AUTOSAR XML (schema 4-3-0)
standard types defined: Boolean, UInt8, SInt8, UInt16, SInt16, UInt32, SInt32, boolean, uint8, sint8, uint16, sint16, uint32, sint32
package /Components
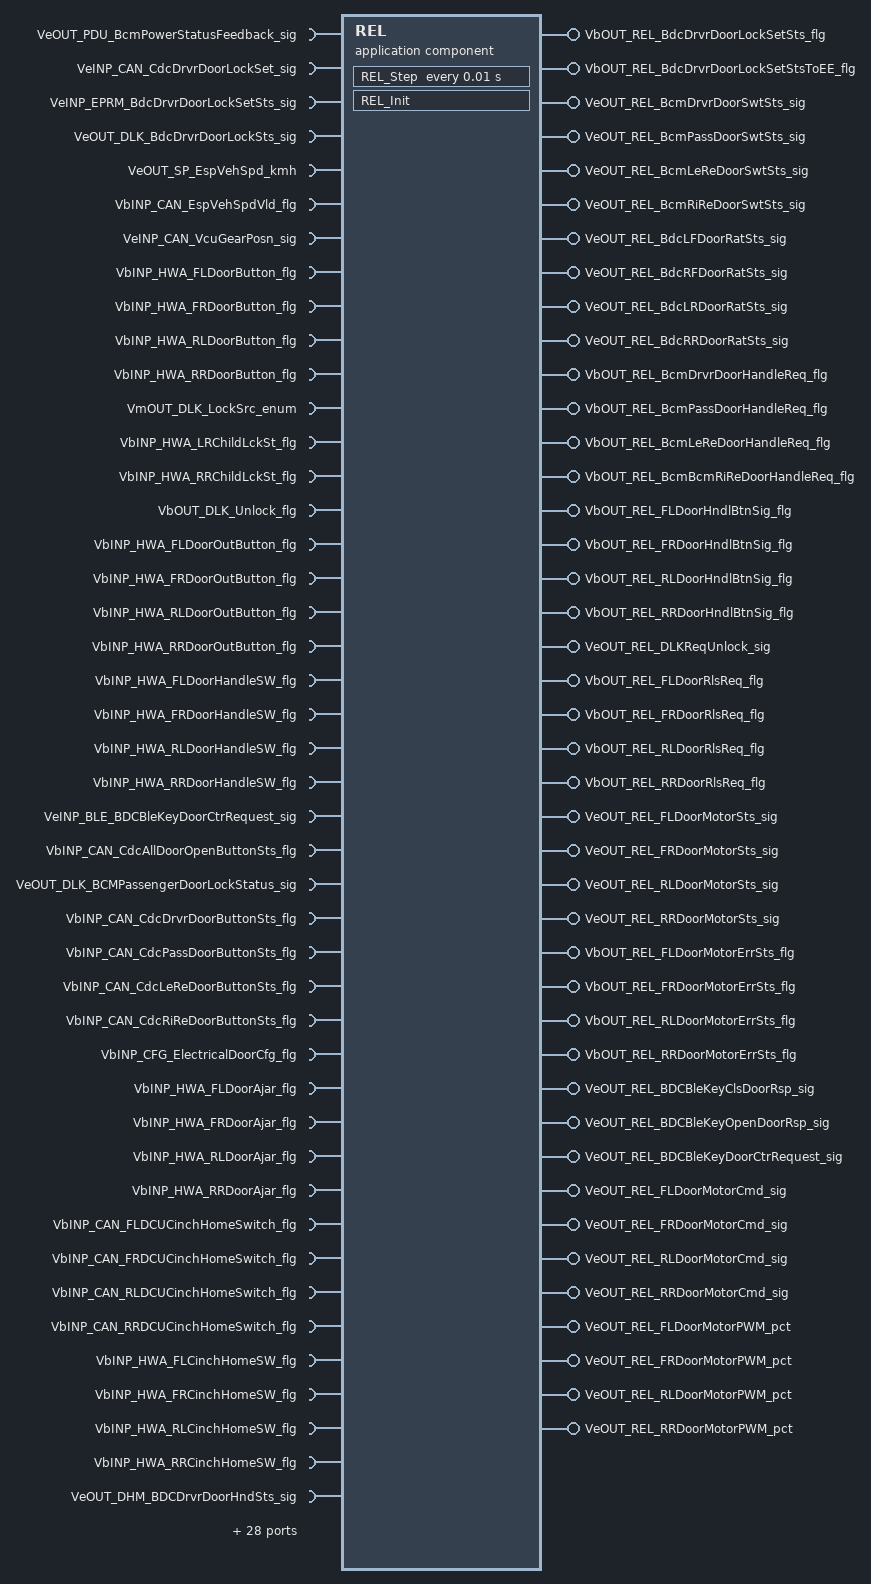
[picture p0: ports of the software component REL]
  application sw component type REL
    74 x require port:
      VeOUT_PDU_BcmPowerStatusFeedback_sig: nonqueued-receiver-com-spec{data-element=VeOUT_PDU_BcmPowerStatusFeedback_sig, init-value=0}, required-interface=VeOUT_PDU_BcmPowerStatusFeedback_sig
      VeINP_CAN_CdcDrvrDoorLockSet_sig: nonqueued-receiver-com-spec{data-element=VeINP_CAN_CdcDrvrDoorLockSet_sig, init-value=0}, required-interface=VeINP_CAN_CdcDrvrDoorLockSet_sig
      VeINP_EPRM_BdcDrvrDoorLockSetSts_sig: nonqueued-receiver-com-spec{data-element=VeINP_EPRM_BdcDrvrDoorLockSetSts_sig, init-value=0}, required-interface=VeINP_EPRM_BdcDrvrDoorLockSetSts_sig
      VeOUT_DLK_BdcDrvrDoorLockSts_sig: nonqueued-receiver-com-spec{data-element=VeOUT_DLK_BdcDrvrDoorLockSts_sig, init-value=0}, required-interface=VeOUT_DLK_BdcDrvrDoorLockSts_sig
      VeOUT_SP_EspVehSpd_kmh: nonqueued-receiver-com-spec{data-element=VeOUT_SP_EspVehSpd_kmh, init-value=0}, required-interface=VeOUT_SP_EspVehSpd_kmh
      VbINP_CAN_EspVehSpdVld_flg: nonqueued-receiver-com-spec{data-element=VbINP_CAN_EspVehSpdVld_flg, init-value=0}, required-interface=VbINP_CAN_EspVehSpdVld_flg
      VeINP_CAN_VcuGearPosn_sig: nonqueued-receiver-com-spec{data-element=VeINP_CAN_VcuGearPosn_sig, init-value=0}, required-interface=VeINP_CAN_VcuGearPosn_sig
      VbINP_HWA_FLDoorButton_flg: nonqueued-receiver-com-spec{data-element=VbINP_HWA_FLDoorButton_flg, init-value=0}, required-interface=VbINP_HWA_FLDoorButton_flg
      VbINP_HWA_FRDoorButton_flg: nonqueued-receiver-com-spec{data-element=VbINP_HWA_FRDoorButton_flg, init-value=0}, required-interface=VbINP_HWA_FRDoorButton_flg
      VbINP_HWA_RLDoorButton_flg: nonqueued-receiver-com-spec{data-element=VbINP_HWA_RLDoorButton_flg, init-value=0}, required-interface=VbINP_HWA_RLDoorButton_flg
      VbINP_HWA_RRDoorButton_flg: nonqueued-receiver-com-spec{data-element=VbINP_HWA_RRDoorButton_flg, init-value=0}, required-interface=VbINP_HWA_RRDoorButton_flg
      VmOUT_DLK_LockSrc_enum: nonqueued-receiver-com-spec{data-element=VmOUT_DLK_LockSrc_enum, init-value=0}, required-interface=VmOUT_DLK_LockSrc_enum
      VbINP_HWA_LRChildLckSt_flg: nonqueued-receiver-com-spec{data-element=VbINP_HWA_LRChildLckSt_flg, init-value=0}, required-interface=VbINP_HWA_LRChildLckSt_flg
      VbINP_HWA_RRChildLckSt_flg: nonqueued-receiver-com-spec{data-element=VbINP_HWA_RRChildLckSt_flg, init-value=0}, required-interface=VbINP_HWA_RRChildLckSt_flg
      VbOUT_DLK_Unlock_flg: nonqueued-receiver-com-spec{data-element=VbOUT_DLK_Unlock_flg, init-value=0}, required-interface=VbOUT_DLK_Unlock_flg
      VbINP_HWA_FLDoorOutButton_flg: nonqueued-receiver-com-spec{data-element=VbINP_HWA_FLDoorOutButton_flg, init-value=0}, required-interface=VbINP_HWA_FLDoorOutButton_flg
      VbINP_HWA_FRDoorOutButton_flg: nonqueued-receiver-com-spec{data-element=VbINP_HWA_FRDoorOutButton_flg, init-value=0}, required-interface=VbINP_HWA_FRDoorOutButton_flg
      VbINP_HWA_RLDoorOutButton_flg: nonqueued-receiver-com-spec{data-element=VbINP_HWA_RLDoorOutButton_flg, init-value=0}, required-interface=VbINP_HWA_RLDoorOutButton_flg
      VbINP_HWA_RRDoorOutButton_flg: nonqueued-receiver-com-spec{data-element=VbINP_HWA_RRDoorOutButton_flg, init-value=0}, required-interface=VbINP_HWA_RRDoorOutButton_flg
      VbINP_HWA_FLDoorHandleSW_flg: nonqueued-receiver-com-spec{data-element=VbINP_HWA_FLDoorHandleSW_flg, init-value=0}, required-interface=VbINP_HWA_FLDoorHandleSW_flg
      VbINP_HWA_FRDoorHandleSW_flg: nonqueued-receiver-com-spec{data-element=VbINP_HWA_FRDoorHandleSW_flg, init-value=0}, required-interface=VbINP_HWA_FRDoorHandleSW_flg
      VbINP_HWA_RLDoorHandleSW_flg: nonqueued-receiver-com-spec{data-element=VbINP_HWA_RLDoorHandleSW_flg, init-value=0}, required-interface=VbINP_HWA_RLDoorHandleSW_flg
      VbINP_HWA_RRDoorHandleSW_flg: nonqueued-receiver-com-spec{data-element=VbINP_HWA_RRDoorHandleSW_flg, init-value=0}, required-interface=VbINP_HWA_RRDoorHandleSW_flg
      VeINP_BLE_BDCBleKeyDoorCtrRequest_sig: nonqueued-receiver-com-spec{data-element=VeINP_BLE_BDCBleKeyDoorCtrRequest_sig, init-value=0}, required-interface=VeINP_BLE_BDCBleKeyDoorCtrRequest_sig
      VbINP_CAN_CdcAllDoorOpenButtonSts_flg: nonqueued-receiver-com-spec{data-element=VbINP_CAN_CdcAllDoorOpenButtonSts_flg, init-value=0}, required-interface=VbINP_CAN_CdcAllDoorOpenButtonSts_flg
      VeOUT_DLK_BCMPassengerDoorLockStatus_sig: nonqueued-receiver-com-spec{data-element=VeOUT_DLK_BCMPassengerDoorLockStatus_sig, init-value=0}, required-interface=VeOUT_DLK_BCMPassengerDoorLockStatus_sig
      VbINP_CAN_CdcDrvrDoorButtonSts_flg: nonqueued-receiver-com-spec{data-element=VbINP_CAN_CdcDrvrDoorButtonSts_flg, init-value=0}, required-interface=VbINP_CAN_CdcDrvrDoorButtonSts_flg
      VbINP_CAN_CdcPassDoorButtonSts_flg: nonqueued-receiver-com-spec{data-element=VbINP_CAN_CdcPassDoorButtonSts_flg, init-value=0}, required-interface=VbINP_CAN_CdcPassDoorButtonSts_flg
      VbINP_CAN_CdcLeReDoorButtonSts_flg: nonqueued-receiver-com-spec{data-element=VbINP_CAN_CdcLeReDoorButtonSts_flg, init-value=0}, required-interface=VbINP_CAN_CdcLeReDoorButtonSts_flg
      VbINP_CAN_CdcRiReDoorButtonSts_flg: nonqueued-receiver-com-spec{data-element=VbINP_CAN_CdcRiReDoorButtonSts_flg, init-value=0}, required-interface=VbINP_CAN_CdcRiReDoorButtonSts_flg
      VbINP_CFG_ElectricalDoorCfg_flg: nonqueued-receiver-com-spec{data-element=VbINP_CFG_ElectricalDoorCfg_flg, init-value=0}, required-interface=VbINP_CFG_ElectricalDoorCfg_flg
      VbINP_HWA_FLDoorAjar_flg: nonqueued-receiver-com-spec{data-element=VbINP_HWA_FLDoorAjar_flg, init-value=0}, required-interface=VbINP_HWA_FLDoorAjar_flg
      VbINP_HWA_FRDoorAjar_flg: nonqueued-receiver-com-spec{data-element=VbINP_HWA_FRDoorAjar_flg, init-value=0}, required-interface=VbINP_HWA_FRDoorAjar_flg
      VbINP_HWA_RLDoorAjar_flg: nonqueued-receiver-com-spec{data-element=VbINP_HWA_RLDoorAjar_flg, init-value=0}, required-interface=VbINP_HWA_RLDoorAjar_flg
      VbINP_HWA_RRDoorAjar_flg: nonqueued-receiver-com-spec{data-element=VbINP_HWA_RRDoorAjar_flg, init-value=0}, required-interface=VbINP_HWA_RRDoorAjar_flg
      VbINP_CAN_FLDCUCinchHomeSwitch_flg: nonqueued-receiver-com-spec{data-element=VbINP_CAN_FLDCUCinchHomeSwitch_flg, init-value=0}, required-interface=VbINP_CAN_FLDCUCinchHomeSwitch_flg
      VbINP_CAN_FRDCUCinchHomeSwitch_flg: nonqueued-receiver-com-spec{data-element=VbINP_CAN_FRDCUCinchHomeSwitch_flg, init-value=0}, required-interface=VbINP_CAN_FRDCUCinchHomeSwitch_flg
      VbINP_CAN_RLDCUCinchHomeSwitch_flg: nonqueued-receiver-com-spec{data-element=VbINP_CAN_RLDCUCinchHomeSwitch_flg, init-value=0}, required-interface=VbINP_CAN_RLDCUCinchHomeSwitch_flg
      VbINP_CAN_RRDCUCinchHomeSwitch_flg: nonqueued-receiver-com-spec{data-element=VbINP_CAN_RRDCUCinchHomeSwitch_flg, init-value=0}, required-interface=VbINP_CAN_RRDCUCinchHomeSwitch_flg
      VbINP_HWA_FLCinchHomeSW_flg: nonqueued-receiver-com-spec{data-element=VbINP_HWA_FLCinchHomeSW_flg, init-value=0}, required-interface=VbINP_HWA_FLCinchHomeSW_flg
      VbINP_HWA_FRCinchHomeSW_flg: nonqueued-receiver-com-spec{data-element=VbINP_HWA_FRCinchHomeSW_flg, init-value=0}, required-interface=VbINP_HWA_FRCinchHomeSW_flg
      VbINP_HWA_RLCinchHomeSW_flg: nonqueued-receiver-com-spec{data-element=VbINP_HWA_RLCinchHomeSW_flg, init-value=0}, required-interface=VbINP_HWA_RLCinchHomeSW_flg
      VbINP_HWA_RRCinchHomeSW_flg: nonqueued-receiver-com-spec{data-element=VbINP_HWA_RRCinchHomeSW_flg, init-value=0}, required-interface=VbINP_HWA_RRCinchHomeSW_flg
      VeOUT_DHM_BDCDrvrDoorHndSts_sig: nonqueued-receiver-com-spec{data-element=VeOUT_DHM_BDCDrvrDoorHndSts_sig, init-value=0}, required-interface=VeOUT_DHM_BDCDrvrDoorHndSts_sig
      VeOUT_DHM_BDCPassDoorHndSts_sig: nonqueued-receiver-com-spec{data-element=VeOUT_DHM_BDCPassDoorHndSts_sig, init-value=0}, required-interface=VeOUT_DHM_BDCPassDoorHndSts_sig
      VeOUT_DHM_BDCLeReDoorHndSts_sig: nonqueued-receiver-com-spec{data-element=VeOUT_DHM_BDCLeReDoorHndSts_sig, init-value=0}, required-interface=VeOUT_DHM_BDCLeReDoorHndSts_sig
      VeOUT_DHM_BDCRiReDoorHndSts_sig: nonqueued-receiver-com-spec{data-element=VeOUT_DHM_BDCRiReDoorHndSts_sig, init-value=0}, required-interface=VeOUT_DHM_BDCRiReDoorHndSts_sig
      VbOUT_SP_CrashOutpSts_flg: nonqueued-receiver-com-spec{data-element=VbOUT_SP_CrashOutpSts_flg, init-value=0}, required-interface=VbOUT_SP_CrashOutpSts_flg
      VbOUT_DLK_BdcDrvrDoorLockOpenReq_flg: nonqueued-receiver-com-spec{data-element=VbOUT_DLK_BdcDrvrDoorLockOpenReq_flg, init-value=0}, required-interface=VbOUT_DLK_BdcDrvrDoorLockOpenReq_flg
      VbOUT_DHM_BdcDrivDoorHandButtonSts_flg: nonqueued-receiver-com-spec{data-element=VbOUT_DHM_BdcDrivDoorHandButtonSts_flg, init-value=0}, required-interface=VbOUT_DHM_BdcDrivDoorHandButtonSts_flg
      VbOUT_DHM_BdcPassDoorHandButtonSts_flg: nonqueued-receiver-com-spec{data-element=VbOUT_DHM_BdcPassDoorHandButtonSts_flg, init-value=0}, required-interface=VbOUT_DHM_BdcPassDoorHandButtonSts_flg
      VeINP_BLE_BleKey{1..3}Posn_sig: nonqueued-receiver-com-spec{data-element=VeINP_BLE_BleKey{1..3}Posn_sig, init-value=0}, required-interface=VeINP_BLE_BleKey{1..3}Posn_sig
      VuINP_CFG_TiLongPressHndlBtn_sig: nonqueued-receiver-com-spec{data-element=VuINP_CFG_TiLongPressHndlBtn_sig, init-value=0}, required-interface=VuINP_CFG_TiLongPressHndlBtn_sig
      VuINP_CFG_OutsideDoorOpenDelay_sig: nonqueued-receiver-com-spec{data-element=VuINP_CFG_OutsideDoorOpenDelay_sig, init-value=0}, required-interface=VuINP_CFG_OutsideDoorOpenDelay_sig
      VuINP_CFG_InsideDoorOpenDelay_sig: nonqueued-receiver-com-spec{data-element=VuINP_CFG_InsideDoorOpenDelay_sig, init-value=0}, required-interface=VuINP_CFG_InsideDoorOpenDelay_sig
      VuINP_CFG_Ti2xPressDoorSw_sig: nonqueued-receiver-com-spec{data-element=VuINP_CFG_Ti2xPressDoorSw_sig, init-value=0}, required-interface=VuINP_CFG_Ti2xPressDoorSw_sig
      VuINP_CFG_TiRelsActv_sig: nonqueued-receiver-com-spec{data-element=VuINP_CFG_TiRelsActv_sig, init-value=0}, required-interface=VuINP_CFG_TiRelsActv_sig
      VeINP_CFG_TiRelsBrakeActv_sig: nonqueued-receiver-com-spec{data-element=VeINP_CFG_TiRelsBrakeActv_sig, init-value=0}, required-interface=VeINP_CFG_TiRelsBrakeActv_sig
      VuINP_CFG_TiRelsResetActv_sig: nonqueued-receiver-com-spec{data-element=VuINP_CFG_TiRelsResetActv_sig, init-value=0}, required-interface=VuINP_CFG_TiRelsResetActv_sig
      VuINP_CFG_TiRelsBrakehold_sig: nonqueued-receiver-com-spec{data-element=VuINP_CFG_TiRelsBrakehold_sig, init-value=0}, required-interface=VuINP_CFG_TiRelsBrakehold_sig
      VuINP_CFG_TiRelsBrakeholdDelay_sig: nonqueued-receiver-com-spec{data-element=VuINP_CFG_TiRelsBrakeholdDelay_sig, init-value=0}, required-interface=VuINP_CFG_TiRelsBrakeholdDelay_sig
      VuINP_CFG_TiIceBrakeActv_sig: nonqueued-receiver-com-spec{data-element=VuINP_CFG_TiIceBrakeActv_sig, init-value=0}, required-interface=VuINP_CFG_TiIceBrakeActv_sig
      VeINP_CFG_VoltRelsActv_sig: nonqueued-receiver-com-spec{data-element=VeINP_CFG_VoltRelsActv_sig, init-value=0}, required-interface=VeINP_CFG_VoltRelsActv_sig
      VeINP_CFG_VoltRelsBrakeActv_sig: nonqueued-receiver-com-spec{data-element=VeINP_CFG_VoltRelsBrakeActv_sig, init-value=0}, required-interface=VeINP_CFG_VoltRelsBrakeActv_sig
      VeINP_CFG_TiCrashRelsDiable_sig: nonqueued-receiver-com-spec{data-element=VeINP_CFG_TiCrashRelsDiable_sig, init-value=0}, required-interface=VeINP_CFG_TiCrashRelsDiable_sig
      VeINP_CFG_TiBleOpenDoorFb_sig: nonqueued-receiver-com-spec{data-element=VeINP_CFG_TiBleOpenDoorFb_sig, init-value=0}, required-interface=VeINP_CFG_TiBleOpenDoorFb_sig
      VeINP_CFG_TiBleClsDoorFb_sig: nonqueued-receiver-com-spec{data-element=VeINP_CFG_TiBleClsDoorFb_sig, init-value=0}, required-interface=VeINP_CFG_TiBleClsDoorFb_sig
      VeINP_HWA_Voltage_100mV: nonqueued-receiver-com-spec{data-element=VeINP_HWA_Voltage_100mV, init-value=0}, required-interface=VeINP_HWA_Voltage_100mV
      VbINP_HWA_FLDoorOpenSW_flg: nonqueued-receiver-com-spec{data-element=VbINP_HWA_FLDoorOpenSW_flg, init-value=0}, required-interface=VbINP_HWA_FLDoorOpenSW_flg
      VbINP_HWA_FRDoorOpenSW_flg: nonqueued-receiver-com-spec{data-element=VbINP_HWA_FRDoorOpenSW_flg, init-value=0}, required-interface=VbINP_HWA_FRDoorOpenSW_flg
      VbINP_HWA_RLDoorOpenSW_flg: nonqueued-receiver-com-spec{data-element=VbINP_HWA_RLDoorOpenSW_flg, init-value=0}, required-interface=VbINP_HWA_RLDoorOpenSW_flg
      VbINP_HWA_RRDoorOpenSW_flg: nonqueued-receiver-com-spec{data-element=VbINP_HWA_RRDoorOpenSW_flg, init-value=0}, required-interface=VbINP_HWA_RRDoorOpenSW_flg
    42 x provide port:
      VbOUT_REL_BdcDrvrDoorLockSetSts_flg: nonqueued-sender-com-spec{data-element=VbOUT_REL_BdcDrvrDoorLockSetSts_flg, init-value=0}, provided-interface=VbOUT_REL_BdcDrvrDoorLockSetSts_flg
      VbOUT_REL_BdcDrvrDoorLockSetStsToEE_flg: nonqueued-sender-com-spec{data-element=VbOUT_REL_BdcDrvrDoorLockSetStsToEE_flg, init-value=0}, provided-interface=VbOUT_REL_BdcDrvrDoorLockSetStsToEE_flg
      VeOUT_REL_BcmDrvrDoorSwtSts_sig: nonqueued-sender-com-spec{data-element=VeOUT_REL_BcmDrvrDoorSwtSts_sig, init-value=0}, provided-interface=VeOUT_REL_BcmDrvrDoorSwtSts_sig
      VeOUT_REL_BcmPassDoorSwtSts_sig: nonqueued-sender-com-spec{data-element=VeOUT_REL_BcmPassDoorSwtSts_sig, init-value=0}, provided-interface=VeOUT_REL_BcmPassDoorSwtSts_sig
      VeOUT_REL_BcmLeReDoorSwtSts_sig: nonqueued-sender-com-spec{data-element=VeOUT_REL_BcmLeReDoorSwtSts_sig, init-value=0}, provided-interface=VeOUT_REL_BcmLeReDoorSwtSts_sig
      VeOUT_REL_BcmRiReDoorSwtSts_sig: nonqueued-sender-com-spec{data-element=VeOUT_REL_BcmRiReDoorSwtSts_sig, init-value=0}, provided-interface=VeOUT_REL_BcmRiReDoorSwtSts_sig
      VeOUT_REL_BdcLFDoorRatSts_sig: nonqueued-sender-com-spec{data-element=VeOUT_REL_BdcLFDoorRatSts_sig, init-value=0}, provided-interface=VeOUT_REL_BdcLFDoorRatSts_sig
      VeOUT_REL_BdcRFDoorRatSts_sig: nonqueued-sender-com-spec{data-element=VeOUT_REL_BdcRFDoorRatSts_sig, init-value=0}, provided-interface=VeOUT_REL_BdcRFDoorRatSts_sig
      VeOUT_REL_BdcLRDoorRatSts_sig: nonqueued-sender-com-spec{data-element=VeOUT_REL_BdcLRDoorRatSts_sig, init-value=0}, provided-interface=VeOUT_REL_BdcLRDoorRatSts_sig
      VeOUT_REL_BdcRRDoorRatSts_sig: nonqueued-sender-com-spec{data-element=VeOUT_REL_BdcRRDoorRatSts_sig, init-value=0}, provided-interface=VeOUT_REL_BdcRRDoorRatSts_sig
      VbOUT_REL_BcmDrvrDoorHandleReq_flg: nonqueued-sender-com-spec{data-element=VbOUT_REL_BcmDrvrDoorHandleReq_flg, init-value=0}, provided-interface=VbOUT_REL_BcmDrvrDoorHandleReq_flg
      VbOUT_REL_BcmPassDoorHandleReq_flg: nonqueued-sender-com-spec{data-element=VbOUT_REL_BcmPassDoorHandleReq_flg, init-value=0}, provided-interface=VbOUT_REL_BcmPassDoorHandleReq_flg
      VbOUT_REL_BcmLeReDoorHandleReq_flg: nonqueued-sender-com-spec{data-element=VbOUT_REL_BcmLeReDoorHandleReq_flg, init-value=0}, provided-interface=VbOUT_REL_BcmLeReDoorHandleReq_flg
      VbOUT_REL_BcmBcmRiReDoorHandleReq_flg: nonqueued-sender-com-spec{data-element=VbOUT_REL_BcmBcmRiReDoorHandleReq_flg, init-value=0}, provided-interface=VbOUT_REL_BcmBcmRiReDoorHandleReq_flg
      VbOUT_REL_FLDoorHndlBtnSig_flg: nonqueued-sender-com-spec{data-element=VbOUT_REL_FLDoorHndlBtnSig_flg, init-value=0}, provided-interface=VbOUT_REL_FLDoorHndlBtnSig_flg
      VbOUT_REL_FRDoorHndlBtnSig_flg: nonqueued-sender-com-spec{data-element=VbOUT_REL_FRDoorHndlBtnSig_flg, init-value=0}, provided-interface=VbOUT_REL_FRDoorHndlBtnSig_flg
      VbOUT_REL_RLDoorHndlBtnSig_flg: nonqueued-sender-com-spec{data-element=VbOUT_REL_RLDoorHndlBtnSig_flg, init-value=0}, provided-interface=VbOUT_REL_RLDoorHndlBtnSig_flg
      VbOUT_REL_RRDoorHndlBtnSig_flg: nonqueued-sender-com-spec{data-element=VbOUT_REL_RRDoorHndlBtnSig_flg, init-value=0}, provided-interface=VbOUT_REL_RRDoorHndlBtnSig_flg
      VeOUT_REL_DLKReqUnlock_sig: nonqueued-sender-com-spec{data-element=VeOUT_REL_DLKReqUnlock_sig, init-value=0}, provided-interface=VeOUT_REL_DLKReqUnlock_sig
      VbOUT_REL_FLDoorRlsReq_flg: nonqueued-sender-com-spec{data-element=VbOUT_REL_FLDoorRlsReq_flg, init-value=0}, provided-interface=VbOUT_REL_FLDoorRlsReq_flg
      VbOUT_REL_FRDoorRlsReq_flg: nonqueued-sender-com-spec{data-element=VbOUT_REL_FRDoorRlsReq_flg, init-value=0}, provided-interface=VbOUT_REL_FRDoorRlsReq_flg
      VbOUT_REL_RLDoorRlsReq_flg: nonqueued-sender-com-spec{data-element=VbOUT_REL_RLDoorRlsReq_flg, init-value=0}, provided-interface=VbOUT_REL_RLDoorRlsReq_flg
      VbOUT_REL_RRDoorRlsReq_flg: nonqueued-sender-com-spec{data-element=VbOUT_REL_RRDoorRlsReq_flg, init-value=0}, provided-interface=VbOUT_REL_RRDoorRlsReq_flg
      VeOUT_REL_FLDoorMotorSts_sig: nonqueued-sender-com-spec{data-element=VeOUT_REL_FLDoorMotorSts_sig, init-value=0}, provided-interface=VeOUT_REL_FLDoorMotorSts_sig
      VeOUT_REL_FRDoorMotorSts_sig: nonqueued-sender-com-spec{data-element=VeOUT_REL_FRDoorMotorSts_sig, init-value=0}, provided-interface=VeOUT_REL_FRDoorMotorSts_sig
      VeOUT_REL_RLDoorMotorSts_sig: nonqueued-sender-com-spec{data-element=VeOUT_REL_RLDoorMotorSts_sig, init-value=0}, provided-interface=VeOUT_REL_RLDoorMotorSts_sig
      VeOUT_REL_RRDoorMotorSts_sig: nonqueued-sender-com-spec{data-element=VeOUT_REL_RRDoorMotorSts_sig, init-value=0}, provided-interface=VeOUT_REL_RRDoorMotorSts_sig
      VbOUT_REL_FLDoorMotorErrSts_flg: nonqueued-sender-com-spec{data-element=VbOUT_REL_FLDoorMotorErrSts_flg, init-value=0}, provided-interface=VbOUT_REL_FLDoorMotorErrSts_flg
      VbOUT_REL_FRDoorMotorErrSts_flg: nonqueued-sender-com-spec{data-element=VbOUT_REL_FRDoorMotorErrSts_flg, init-value=0}, provided-interface=VbOUT_REL_FRDoorMotorErrSts_flg
      VbOUT_REL_RLDoorMotorErrSts_flg: nonqueued-sender-com-spec{data-element=VbOUT_REL_RLDoorMotorErrSts_flg, init-value=0}, provided-interface=VbOUT_REL_RLDoorMotorErrSts_flg
      VbOUT_REL_RRDoorMotorErrSts_flg: nonqueued-sender-com-spec{data-element=VbOUT_REL_RRDoorMotorErrSts_flg, init-value=0}, provided-interface=VbOUT_REL_RRDoorMotorErrSts_flg
      VeOUT_REL_BDCBleKeyClsDoorRsp_sig: nonqueued-sender-com-spec{data-element=VeOUT_REL_BDCBleKeyClsDoorRsp_sig, init-value=0}, provided-interface=VeOUT_REL_BDCBleKeyClsDoorRsp_sig
      VeOUT_REL_BDCBleKeyOpenDoorRsp_sig: nonqueued-sender-com-spec{data-element=VeOUT_REL_BDCBleKeyOpenDoorRsp_sig, init-value=0}, provided-interface=VeOUT_REL_BDCBleKeyOpenDoorRsp_sig
      VeOUT_REL_BDCBleKeyDoorCtrRequest_sig: nonqueued-sender-com-spec{data-element=VeOUT_REL_BDCBleKeyDoorCtrRequest_sig, init-value=0}, provided-interface=VeOUT_REL_BDCBleKeyDoorCtrRequest_sig
      VeOUT_REL_FLDoorMotorCmd_sig: nonqueued-sender-com-spec{data-element=VeOUT_REL_FLDoorMotorCmd_sig, init-value=0}, provided-interface=VeOUT_REL_FLDoorMotorCmd_sig
      VeOUT_REL_FRDoorMotorCmd_sig: nonqueued-sender-com-spec{data-element=VeOUT_REL_FRDoorMotorCmd_sig, init-value=0}, provided-interface=VeOUT_REL_FRDoorMotorCmd_sig
      VeOUT_REL_RLDoorMotorCmd_sig: nonqueued-sender-com-spec{data-element=VeOUT_REL_RLDoorMotorCmd_sig, init-value=0}, provided-interface=VeOUT_REL_RLDoorMotorCmd_sig
      VeOUT_REL_RRDoorMotorCmd_sig: nonqueued-sender-com-spec{data-element=VeOUT_REL_RRDoorMotorCmd_sig, init-value=0}, provided-interface=VeOUT_REL_RRDoorMotorCmd_sig
      VeOUT_REL_FLDoorMotorPWM_pct: nonqueued-sender-com-spec{data-element=VeOUT_REL_FLDoorMotorPWM_pct, init-value=0}, provided-interface=VeOUT_REL_FLDoorMotorPWM_pct
      VeOUT_REL_FRDoorMotorPWM_pct: nonqueued-sender-com-spec{data-element=VeOUT_REL_FRDoorMotorPWM_pct, init-value=0}, provided-interface=VeOUT_REL_FRDoorMotorPWM_pct
      VeOUT_REL_RLDoorMotorPWM_pct: nonqueued-sender-com-spec{data-element=VeOUT_REL_RLDoorMotorPWM_pct, init-value=0}, provided-interface=VeOUT_REL_RLDoorMotorPWM_pct
      VeOUT_REL_RRDoorMotorPWM_pct: nonqueued-sender-com-spec{data-element=VeOUT_REL_RRDoorMotorPWM_pct, init-value=0}, provided-interface=VeOUT_REL_RRDoorMotorPWM_pct
    behavior REL: data-type-mapping=DataTypeMappingsSet, handle-termination-and-restart=NO-SUPPORT
      init event REL_InitEvent: start-on-event=REL_Init
      timing event Event_Runnable_Step: start-on-event=REL_Step, period=0.01
      runnable REL_Init
      runnable REL_Step
        data-receive-point-by-arguments:
          74 x access:
            IN_VeOUT_PDU_BcmPowerStatusFeedback_sig_VeOUT_PDU_BcmPowerStatusFeedback_sig: accessed-variable=VeOUT_PDU_BcmPowerStatusFeedback_sig.VeOUT_PDU_BcmPowerStatusFeedback_sig
            IN_VeINP_CAN_CdcDrvrDoorLockSet_sig_VeINP_CAN_CdcDrvrDoorLockSet_sig: accessed-variable=VeINP_CAN_CdcDrvrDoorLockSet_sig.VeINP_CAN_CdcDrvrDoorLockSet_sig
            IN_VeINP_EPRM_BdcDrvrDoorLockSetSts_sig_VeINP_EPRM_BdcDrvrDoorLockSetSts_sig: accessed-variable=VeINP_EPRM_BdcDrvrDoorLockSetSts_sig.VeINP_EPRM_BdcDrvrDoorLockSetSts_sig
            IN_VeOUT_DLK_BdcDrvrDoorLockSts_sig_VeOUT_DLK_BdcDrvrDoorLockSts_sig: accessed-variable=VeOUT_DLK_BdcDrvrDoorLockSts_sig.VeOUT_DLK_BdcDrvrDoorLockSts_sig
            IN_VeOUT_SP_EspVehSpd_kmh_VeOUT_SP_EspVehSpd_kmh: accessed-variable=VeOUT_SP_EspVehSpd_kmh.VeOUT_SP_EspVehSpd_kmh
            IN_VbINP_CAN_EspVehSpdVld_flg_VbINP_CAN_EspVehSpdVld_flg: accessed-variable=VbINP_CAN_EspVehSpdVld_flg.VbINP_CAN_EspVehSpdVld_flg
            IN_VeINP_CAN_VcuGearPosn_sig_VeINP_CAN_VcuGearPosn_sig: accessed-variable=VeINP_CAN_VcuGearPosn_sig.VeINP_CAN_VcuGearPosn_sig
            IN_VbINP_HWA_FLDoorButton_flg_VbINP_HWA_FLDoorButton_flg: accessed-variable=VbINP_HWA_FLDoorButton_flg.VbINP_HWA_FLDoorButton_flg
            IN_VbINP_HWA_FRDoorButton_flg_VbINP_HWA_FRDoorButton_flg: accessed-variable=VbINP_HWA_FRDoorButton_flg.VbINP_HWA_FRDoorButton_flg
            IN_VbINP_HWA_RLDoorButton_flg_VbINP_HWA_RLDoorButton_flg: accessed-variable=VbINP_HWA_RLDoorButton_flg.VbINP_HWA_RLDoorButton_flg
            IN_VbINP_HWA_RRDoorButton_flg_VbINP_HWA_RRDoorButton_flg: accessed-variable=VbINP_HWA_RRDoorButton_flg.VbINP_HWA_RRDoorButton_flg
            IN_VmOUT_DLK_LockSrc_enum_VmOUT_DLK_LockSrc_enum: accessed-variable=VmOUT_DLK_LockSrc_enum.VmOUT_DLK_LockSrc_enum
            IN_VbINP_HWA_LRChildLckSt_flg_VbINP_HWA_LRChildLckSt_flg: accessed-variable=VbINP_HWA_LRChildLckSt_flg.VbINP_HWA_LRChildLckSt_flg
            IN_VbINP_HWA_RRChildLckSt_flg_VbINP_HWA_RRChildLckSt_flg: accessed-variable=VbINP_HWA_RRChildLckSt_flg.VbINP_HWA_RRChildLckSt_flg
            IN_VbOUT_DLK_Unlock_flg_VbOUT_DLK_Unlock_flg: accessed-variable=VbOUT_DLK_Unlock_flg.VbOUT_DLK_Unlock_flg
            IN_VbINP_HWA_FLDoorOutButton_flg_VbINP_HWA_FLDoorOutButton_flg: accessed-variable=VbINP_HWA_FLDoorOutButton_flg.VbINP_HWA_FLDoorOutButton_flg
            IN_VbINP_HWA_FRDoorOutButton_flg_VbINP_HWA_FRDoorOutButton_flg: accessed-variable=VbINP_HWA_FRDoorOutButton_flg.VbINP_HWA_FRDoorOutButton_flg
            IN_VbINP_HWA_RLDoorOutButton_flg_VbINP_HWA_RLDoorOutButton_flg: accessed-variable=VbINP_HWA_RLDoorOutButton_flg.VbINP_HWA_RLDoorOutButton_flg
            IN_VbINP_HWA_RRDoorOutButton_flg_VbINP_HWA_RRDoorOutButton_flg: accessed-variable=VbINP_HWA_RRDoorOutButton_flg.VbINP_HWA_RRDoorOutButton_flg
            IN_VbINP_HWA_FLDoorHandleSW_flg_VbINP_HWA_FLDoorHandleSW_flg: accessed-variable=VbINP_HWA_FLDoorHandleSW_flg.VbINP_HWA_FLDoorHandleSW_flg
            IN_VbINP_HWA_FRDoorHandleSW_flg_VbINP_HWA_FRDoorHandleSW_flg: accessed-variable=VbINP_HWA_FRDoorHandleSW_flg.VbINP_HWA_FRDoorHandleSW_flg
            IN_VbINP_HWA_RLDoorHandleSW_flg_VbINP_HWA_RLDoorHandleSW_flg: accessed-variable=VbINP_HWA_RLDoorHandleSW_flg.VbINP_HWA_RLDoorHandleSW_flg
            IN_VbINP_HWA_RRDoorHandleSW_flg_VbINP_HWA_RRDoorHandleSW_flg: accessed-variable=VbINP_HWA_RRDoorHandleSW_flg.VbINP_HWA_RRDoorHandleSW_flg
            IN_VeINP_BLE_BDCBleKeyDoorCtrRequest_sig_VeINP_BLE_BDCBleKeyDoorCtrRequest_sig: accessed-variable=VeINP_BLE_BDCBleKeyDoorCtrRequest_sig.VeINP_BLE_BDCBleKeyDoorCtrRequest_sig
            IN_VbINP_CAN_CdcAllDoorOpenButtonSts_flg_VbINP_CAN_CdcAllDoorOpenButtonSts_flg: accessed-variable=VbINP_CAN_CdcAllDoorOpenButtonSts_flg.VbINP_CAN_CdcAllDoorOpenButtonSts_flg
            IN_VeOUT_DLK_BCMPassengerDoorLockStatus_sig_VeOUT_DLK_BCMPassengerDoorLockStatus_sig: accessed-variable=VeOUT_DLK_BCMPassengerDoorLockStatus_sig.VeOUT_DLK_BCMPassengerDoorLockStatus_sig
            IN_VbINP_CAN_CdcDrvrDoorButtonSts_flg_VbINP_CAN_CdcDrvrDoorButtonSts_flg: accessed-variable=VbINP_CAN_CdcDrvrDoorButtonSts_flg.VbINP_CAN_CdcDrvrDoorButtonSts_flg
            IN_VbINP_CAN_CdcPassDoorButtonSts_flg_VbINP_CAN_CdcPassDoorButtonSts_flg: accessed-variable=VbINP_CAN_CdcPassDoorButtonSts_flg.VbINP_CAN_CdcPassDoorButtonSts_flg
            IN_VbINP_CAN_CdcLeReDoorButtonSts_flg_VbINP_CAN_CdcLeReDoorButtonSts_flg: accessed-variable=VbINP_CAN_CdcLeReDoorButtonSts_flg.VbINP_CAN_CdcLeReDoorButtonSts_flg
            IN_VbINP_CAN_CdcRiReDoorButtonSts_flg_VbINP_CAN_CdcRiReDoorButtonSts_flg: accessed-variable=VbINP_CAN_CdcRiReDoorButtonSts_flg.VbINP_CAN_CdcRiReDoorButtonSts_flg
            IN_VbINP_CFG_ElectricalDoorCfg_flg_VbINP_CFG_ElectricalDoorCfg_flg: accessed-variable=VbINP_CFG_ElectricalDoorCfg_flg.VbINP_CFG_ElectricalDoorCfg_flg
            IN_VbINP_HWA_FLDoorAjar_flg_VbINP_HWA_FLDoorAjar_flg: accessed-variable=VbINP_HWA_FLDoorAjar_flg.VbINP_HWA_FLDoorAjar_flg
            IN_VbINP_HWA_FRDoorAjar_flg_VbINP_HWA_FRDoorAjar_flg: accessed-variable=VbINP_HWA_FRDoorAjar_flg.VbINP_HWA_FRDoorAjar_flg
            IN_VbINP_HWA_RLDoorAjar_flg_VbINP_HWA_RLDoorAjar_flg: accessed-variable=VbINP_HWA_RLDoorAjar_flg.VbINP_HWA_RLDoorAjar_flg
            IN_VbINP_HWA_RRDoorAjar_flg_VbINP_HWA_RRDoorAjar_flg: accessed-variable=VbINP_HWA_RRDoorAjar_flg.VbINP_HWA_RRDoorAjar_flg
            IN_VbINP_CAN_FLDCUCinchHomeSwitch_flg_VbINP_CAN_FLDCUCinchHomeSwitch_flg: accessed-variable=VbINP_CAN_FLDCUCinchHomeSwitch_flg.VbINP_CAN_FLDCUCinchHomeSwitch_flg
            IN_VbINP_CAN_FRDCUCinchHomeSwitch_flg_VbINP_CAN_FRDCUCinchHomeSwitch_flg: accessed-variable=VbINP_CAN_FRDCUCinchHomeSwitch_flg.VbINP_CAN_FRDCUCinchHomeSwitch_flg
            IN_VbINP_CAN_RLDCUCinchHomeSwitch_flg_VbINP_CAN_RLDCUCinchHomeSwitch_flg: accessed-variable=VbINP_CAN_RLDCUCinchHomeSwitch_flg.VbINP_CAN_RLDCUCinchHomeSwitch_flg
            IN_VbINP_CAN_RRDCUCinchHomeSwitch_flg_VbINP_CAN_RRDCUCinchHomeSwitch_flg: accessed-variable=VbINP_CAN_RRDCUCinchHomeSwitch_flg.VbINP_CAN_RRDCUCinchHomeSwitch_flg
            IN_VbINP_HWA_FLCinchHomeSW_flg_VbINP_HWA_FLCinchHomeSW_flg: accessed-variable=VbINP_HWA_FLCinchHomeSW_flg.VbINP_HWA_FLCinchHomeSW_flg
            IN_VbINP_HWA_FRCinchHomeSW_flg_VbINP_HWA_FRCinchHomeSW_flg: accessed-variable=VbINP_HWA_FRCinchHomeSW_flg.VbINP_HWA_FRCinchHomeSW_flg
            IN_VbINP_HWA_RLCinchHomeSW_flg_VbINP_HWA_RLCinchHomeSW_flg: accessed-variable=VbINP_HWA_RLCinchHomeSW_flg.VbINP_HWA_RLCinchHomeSW_flg
            IN_VbINP_HWA_RRCinchHomeSW_flg_VbINP_HWA_RRCinchHomeSW_flg: accessed-variable=VbINP_HWA_RRCinchHomeSW_flg.VbINP_HWA_RRCinchHomeSW_flg
            IN_VeOUT_DHM_BDCDrvrDoorHndSts_sig_VeOUT_DHM_BDCDrvrDoorHndSts_sig: accessed-variable=VeOUT_DHM_BDCDrvrDoorHndSts_sig.VeOUT_DHM_BDCDrvrDoorHndSts_sig
            IN_VeOUT_DHM_BDCPassDoorHndSts_sig_VeOUT_DHM_BDCPassDoorHndSts_sig: accessed-variable=VeOUT_DHM_BDCPassDoorHndSts_sig.VeOUT_DHM_BDCPassDoorHndSts_sig
            IN_VeOUT_DHM_BDCLeReDoorHndSts_sig_VeOUT_DHM_BDCLeReDoorHndSts_sig: accessed-variable=VeOUT_DHM_BDCLeReDoorHndSts_sig.VeOUT_DHM_BDCLeReDoorHndSts_sig
            IN_VeOUT_DHM_BDCRiReDoorHndSts_sig_VeOUT_DHM_BDCRiReDoorHndSts_sig: accessed-variable=VeOUT_DHM_BDCRiReDoorHndSts_sig.VeOUT_DHM_BDCRiReDoorHndSts_sig
            IN_VbOUT_SP_CrashOutpSts_flg_VbOUT_SP_CrashOutpSts_flg: accessed-variable=VbOUT_SP_CrashOutpSts_flg.VbOUT_SP_CrashOutpSts_flg
            IN_VbOUT_DLK_BdcDrvrDoorLockOpenReq_flg_VbOUT_DLK_BdcDrvrDoorLockOpenReq_flg: accessed-variable=VbOUT_DLK_BdcDrvrDoorLockOpenReq_flg.VbOUT_DLK_BdcDrvrDoorLockOpenReq_flg
            IN_VbOUT_DHM_BdcDrivDoorHandButtonSts_flg_VbOUT_DHM_BdcDrivDoorHandButtonSts_flg: accessed-variable=VbOUT_DHM_BdcDrivDoorHandButtonSts_flg.VbOUT_DHM_BdcDrivDoorHandButtonSts_flg
            IN_VbOUT_DHM_BdcPassDoorHandButtonSts_flg_VbOUT_DHM_BdcPassDoorHandButtonSts_flg: accessed-variable=VbOUT_DHM_BdcPassDoorHandButtonSts_flg.VbOUT_DHM_BdcPassDoorHandButtonSts_flg
            IN_VeINP_BLE_BleKey{1..3}Posn_sig_VeINP_BLE_BleKey{1..3}Posn_sig: accessed-variable=VeINP_BLE_BleKey{1..3}Posn_sig.VeINP_BLE_BleKey{1..3}Posn_sig
            IN_VuINP_CFG_TiLongPressHndlBtn_sig_VuINP_CFG_TiLongPressHndlBtn_sig: accessed-variable=VuINP_CFG_TiLongPressHndlBtn_sig.VuINP_CFG_TiLongPressHndlBtn_sig
            IN_VuINP_CFG_OutsideDoorOpenDelay_sig_VuINP_CFG_OutsideDoorOpenDelay_sig: accessed-variable=VuINP_CFG_OutsideDoorOpenDelay_sig.VuINP_CFG_OutsideDoorOpenDelay_sig
            IN_VuINP_CFG_InsideDoorOpenDelay_sig_VuINP_CFG_InsideDoorOpenDelay_sig: accessed-variable=VuINP_CFG_InsideDoorOpenDelay_sig.VuINP_CFG_InsideDoorOpenDelay_sig
            IN_VuINP_CFG_Ti2xPressDoorSw_sig_VuINP_CFG_Ti2xPressDoorSw_sig: accessed-variable=VuINP_CFG_Ti2xPressDoorSw_sig.VuINP_CFG_Ti2xPressDoorSw_sig
            IN_VuINP_CFG_TiRelsActv_sig_VuINP_CFG_TiRelsActv_sig: accessed-variable=VuINP_CFG_TiRelsActv_sig.VuINP_CFG_TiRelsActv_sig
            IN_VeINP_CFG_TiRelsBrakeActv_sig_VeINP_CFG_TiRelsBrakeActv_sig: accessed-variable=VeINP_CFG_TiRelsBrakeActv_sig.VeINP_CFG_TiRelsBrakeActv_sig
            IN_VuINP_CFG_TiRelsResetActv_sig_VuINP_CFG_TiRelsResetActv_sig: accessed-variable=VuINP_CFG_TiRelsResetActv_sig.VuINP_CFG_TiRelsResetActv_sig
            IN_VuINP_CFG_TiRelsBrakehold_sig_VuINP_CFG_TiRelsBrakehold_sig: accessed-variable=VuINP_CFG_TiRelsBrakehold_sig.VuINP_CFG_TiRelsBrakehold_sig
            IN_VuINP_CFG_TiRelsBrakeholdDelay_sig_VuINP_CFG_TiRelsBrakeholdDelay_sig: accessed-variable=VuINP_CFG_TiRelsBrakeholdDelay_sig.VuINP_CFG_TiRelsBrakeholdDelay_sig
            IN_VuINP_CFG_TiIceBrakeActv_sig_VuINP_CFG_TiIceBrakeActv_sig: accessed-variable=VuINP_CFG_TiIceBrakeActv_sig.VuINP_CFG_TiIceBrakeActv_sig
            IN_VeINP_CFG_VoltRelsActv_sig_VeINP_CFG_VoltRelsActv_sig: accessed-variable=VeINP_CFG_VoltRelsActv_sig.VeINP_CFG_VoltRelsActv_sig
            IN_VeINP_CFG_VoltRelsBrakeActv_sig_VeINP_CFG_VoltRelsBrakeActv_sig: accessed-variable=VeINP_CFG_VoltRelsBrakeActv_sig.VeINP_CFG_VoltRelsBrakeActv_sig
            IN_VeINP_CFG_TiCrashRelsDiable_sig_VeINP_CFG_TiCrashRelsDiable_sig: accessed-variable=VeINP_CFG_TiCrashRelsDiable_sig.VeINP_CFG_TiCrashRelsDiable_sig
            IN_VeINP_CFG_TiBleOpenDoorFb_sig_VeINP_CFG_TiBleOpenDoorFb_sig: accessed-variable=VeINP_CFG_TiBleOpenDoorFb_sig.VeINP_CFG_TiBleOpenDoorFb_sig
            IN_VeINP_CFG_TiBleClsDoorFb_sig_VeINP_CFG_TiBleClsDoorFb_sig: accessed-variable=VeINP_CFG_TiBleClsDoorFb_sig.VeINP_CFG_TiBleClsDoorFb_sig
            IN_VeINP_HWA_Voltage_100mV_VeINP_HWA_Voltage_100mV: accessed-variable=VeINP_HWA_Voltage_100mV.VeINP_HWA_Voltage_100mV
            IN_VbINP_HWA_FLDoorOpenSW_flg_VbINP_HWA_FLDoorOpenSW_flg: accessed-variable=VbINP_HWA_FLDoorOpenSW_flg.VbINP_HWA_FLDoorOpenSW_flg
            IN_VbINP_HWA_FRDoorOpenSW_flg_VbINP_HWA_FRDoorOpenSW_flg: accessed-variable=VbINP_HWA_FRDoorOpenSW_flg.VbINP_HWA_FRDoorOpenSW_flg
            IN_VbINP_HWA_RLDoorOpenSW_flg_VbINP_HWA_RLDoorOpenSW_flg: accessed-variable=VbINP_HWA_RLDoorOpenSW_flg.VbINP_HWA_RLDoorOpenSW_flg
            IN_VbINP_HWA_RRDoorOpenSW_flg_VbINP_HWA_RRDoorOpenSW_flg: accessed-variable=VbINP_HWA_RRDoorOpenSW_flg.VbINP_HWA_RRDoorOpenSW_flg
        data-send-points:
          42 x access:
            OUT_VbOUT_REL_BdcDrvrDoorLockSetSts_flg_VbOUT_REL_BdcDrvrDoorLockSetSts_flg: accessed-variable=VbOUT_REL_BdcDrvrDoorLockSetSts_flg.VbOUT_REL_BdcDrvrDoorLockSetSts_flg
            OUT_VbOUT_REL_BdcDrvrDoorLockSetStsToEE_flg_VbOUT_REL_BdcDrvrDoorLockSetStsToEE_flg: accessed-variable=VbOUT_REL_BdcDrvrDoorLockSetStsToEE_flg.VbOUT_REL_BdcDrvrDoorLockSetStsToEE_flg
            OUT_VeOUT_REL_BcmDrvrDoorSwtSts_sig_VeOUT_REL_BcmDrvrDoorSwtSts_sig: accessed-variable=VeOUT_REL_BcmDrvrDoorSwtSts_sig.VeOUT_REL_BcmDrvrDoorSwtSts_sig
            OUT_VeOUT_REL_BcmPassDoorSwtSts_sig_VeOUT_REL_BcmPassDoorSwtSts_sig: accessed-variable=VeOUT_REL_BcmPassDoorSwtSts_sig.VeOUT_REL_BcmPassDoorSwtSts_sig
            OUT_VeOUT_REL_BcmLeReDoorSwtSts_sig_VeOUT_REL_BcmLeReDoorSwtSts_sig: accessed-variable=VeOUT_REL_BcmLeReDoorSwtSts_sig.VeOUT_REL_BcmLeReDoorSwtSts_sig
            OUT_VeOUT_REL_BcmRiReDoorSwtSts_sig_VeOUT_REL_BcmRiReDoorSwtSts_sig: accessed-variable=VeOUT_REL_BcmRiReDoorSwtSts_sig.VeOUT_REL_BcmRiReDoorSwtSts_sig
            OUT_VeOUT_REL_BdcLFDoorRatSts_sig_VeOUT_REL_BdcLFDoorRatSts_sig: accessed-variable=VeOUT_REL_BdcLFDoorRatSts_sig.VeOUT_REL_BdcLFDoorRatSts_sig
            OUT_VeOUT_REL_BdcRFDoorRatSts_sig_VeOUT_REL_BdcRFDoorRatSts_sig: accessed-variable=VeOUT_REL_BdcRFDoorRatSts_sig.VeOUT_REL_BdcRFDoorRatSts_sig
            OUT_VeOUT_REL_BdcLRDoorRatSts_sig_VeOUT_REL_BdcLRDoorRatSts_sig: accessed-variable=VeOUT_REL_BdcLRDoorRatSts_sig.VeOUT_REL_BdcLRDoorRatSts_sig
            OUT_VeOUT_REL_BdcRRDoorRatSts_sig_VeOUT_REL_BdcRRDoorRatSts_sig: accessed-variable=VeOUT_REL_BdcRRDoorRatSts_sig.VeOUT_REL_BdcRRDoorRatSts_sig
            OUT_VbOUT_REL_BcmDrvrDoorHandleReq_flg_VbOUT_REL_BcmDrvrDoorHandleReq_flg: accessed-variable=VbOUT_REL_BcmDrvrDoorHandleReq_flg.VbOUT_REL_BcmDrvrDoorHandleReq_flg
            OUT_VbOUT_REL_BcmPassDoorHandleReq_flg_VbOUT_REL_BcmPassDoorHandleReq_flg: accessed-variable=VbOUT_REL_BcmPassDoorHandleReq_flg.VbOUT_REL_BcmPassDoorHandleReq_flg
            OUT_VbOUT_REL_BcmLeReDoorHandleReq_flg_VbOUT_REL_BcmLeReDoorHandleReq_flg: accessed-variable=VbOUT_REL_BcmLeReDoorHandleReq_flg.VbOUT_REL_BcmLeReDoorHandleReq_flg
            OUT_VbOUT_REL_BcmBcmRiReDoorHandleReq_flg_VbOUT_REL_BcmBcmRiReDoorHandleReq_flg: accessed-variable=VbOUT_REL_BcmBcmRiReDoorHandleReq_flg.VbOUT_REL_BcmBcmRiReDoorHandleReq_flg
            OUT_VbOUT_REL_FLDoorHndlBtnSig_flg_VbOUT_REL_FLDoorHndlBtnSig_flg: accessed-variable=VbOUT_REL_FLDoorHndlBtnSig_flg.VbOUT_REL_FLDoorHndlBtnSig_flg
            OUT_VbOUT_REL_FRDoorHndlBtnSig_flg_VbOUT_REL_FRDoorHndlBtnSig_flg: accessed-variable=VbOUT_REL_FRDoorHndlBtnSig_flg.VbOUT_REL_FRDoorHndlBtnSig_flg
            OUT_VbOUT_REL_RLDoorHndlBtnSig_flg_VbOUT_REL_RLDoorHndlBtnSig_flg: accessed-variable=VbOUT_REL_RLDoorHndlBtnSig_flg.VbOUT_REL_RLDoorHndlBtnSig_flg
            OUT_VbOUT_REL_RRDoorHndlBtnSig_flg_VbOUT_REL_RRDoorHndlBtnSig_flg: accessed-variable=VbOUT_REL_RRDoorHndlBtnSig_flg.VbOUT_REL_RRDoorHndlBtnSig_flg
            OUT_VeOUT_REL_DLKReqUnlock_sig_VeOUT_REL_DLKReqUnlock_sig: accessed-variable=VeOUT_REL_DLKReqUnlock_sig.VeOUT_REL_DLKReqUnlock_sig
            OUT_VbOUT_REL_FLDoorRlsReq_flg_VbOUT_REL_FLDoorRlsReq_flg: accessed-variable=VbOUT_REL_FLDoorRlsReq_flg.VbOUT_REL_FLDoorRlsReq_flg
            OUT_VbOUT_REL_FRDoorRlsReq_flg_VbOUT_REL_FRDoorRlsReq_flg: accessed-variable=VbOUT_REL_FRDoorRlsReq_flg.VbOUT_REL_FRDoorRlsReq_flg
            OUT_VbOUT_REL_RLDoorRlsReq_flg_VbOUT_REL_RLDoorRlsReq_flg: accessed-variable=VbOUT_REL_RLDoorRlsReq_flg.VbOUT_REL_RLDoorRlsReq_flg
            OUT_VbOUT_REL_RRDoorRlsReq_flg_VbOUT_REL_RRDoorRlsReq_flg: accessed-variable=VbOUT_REL_RRDoorRlsReq_flg.VbOUT_REL_RRDoorRlsReq_flg
            OUT_VeOUT_REL_FLDoorMotorSts_sig_VeOUT_REL_FLDoorMotorSts_sig: accessed-variable=VeOUT_REL_FLDoorMotorSts_sig.VeOUT_REL_FLDoorMotorSts_sig
            OUT_VeOUT_REL_FRDoorMotorSts_sig_VeOUT_REL_FRDoorMotorSts_sig: accessed-variable=VeOUT_REL_FRDoorMotorSts_sig.VeOUT_REL_FRDoorMotorSts_sig
            OUT_VeOUT_REL_RLDoorMotorSts_sig_VeOUT_REL_RLDoorMotorSts_sig: accessed-variable=VeOUT_REL_RLDoorMotorSts_sig.VeOUT_REL_RLDoorMotorSts_sig
            OUT_VeOUT_REL_RRDoorMotorSts_sig_VeOUT_REL_RRDoorMotorSts_sig: accessed-variable=VeOUT_REL_RRDoorMotorSts_sig.VeOUT_REL_RRDoorMotorSts_sig
            OUT_VbOUT_REL_FLDoorMotorErrSts_flg_VbOUT_REL_FLDoorMotorErrSts_flg: accessed-variable=VbOUT_REL_FLDoorMotorErrSts_flg.VbOUT_REL_FLDoorMotorErrSts_flg
            OUT_VbOUT_REL_FRDoorMotorErrSts_flg_VbOUT_REL_FRDoorMotorErrSts_flg: accessed-variable=VbOUT_REL_FRDoorMotorErrSts_flg.VbOUT_REL_FRDoorMotorErrSts_flg
            OUT_VbOUT_REL_RLDoorMotorErrSts_flg_VbOUT_REL_RLDoorMotorErrSts_flg: accessed-variable=VbOUT_REL_RLDoorMotorErrSts_flg.VbOUT_REL_RLDoorMotorErrSts_flg
            OUT_VbOUT_REL_RRDoorMotorErrSts_flg_VbOUT_REL_RRDoorMotorErrSts_flg: accessed-variable=VbOUT_REL_RRDoorMotorErrSts_flg.VbOUT_REL_RRDoorMotorErrSts_flg
            OUT_VeOUT_REL_BDCBleKeyClsDoorRsp_sig_VeOUT_REL_BDCBleKeyClsDoorRsp_sig: accessed-variable=VeOUT_REL_BDCBleKeyClsDoorRsp_sig.VeOUT_REL_BDCBleKeyClsDoorRsp_sig
            OUT_VeOUT_REL_BDCBleKeyOpenDoorRsp_sig_VeOUT_REL_BDCBleKeyOpenDoorRsp_sig: accessed-variable=VeOUT_REL_BDCBleKeyOpenDoorRsp_sig.VeOUT_REL_BDCBleKeyOpenDoorRsp_sig
            OUT_VeOUT_REL_BDCBleKeyDoorCtrRequest_sig_VeOUT_REL_BDCBleKeyDoorCtrRequest_sig: accessed-variable=VeOUT_REL_BDCBleKeyDoorCtrRequest_sig.VeOUT_REL_BDCBleKeyDoorCtrRequest_sig
            OUT_VeOUT_REL_FLDoorMotorCmd_sig_VeOUT_REL_FLDoorMotorCmd_sig: accessed-variable=VeOUT_REL_FLDoorMotorCmd_sig.VeOUT_REL_FLDoorMotorCmd_sig
            OUT_VeOUT_REL_FRDoorMotorCmd_sig_VeOUT_REL_FRDoorMotorCmd_sig: accessed-variable=VeOUT_REL_FRDoorMotorCmd_sig.VeOUT_REL_FRDoorMotorCmd_sig
            OUT_VeOUT_REL_RLDoorMotorCmd_sig_VeOUT_REL_RLDoorMotorCmd_sig: accessed-variable=VeOUT_REL_RLDoorMotorCmd_sig.VeOUT_REL_RLDoorMotorCmd_sig
            OUT_VeOUT_REL_RRDoorMotorCmd_sig_VeOUT_REL_RRDoorMotorCmd_sig: accessed-variable=VeOUT_REL_RRDoorMotorCmd_sig.VeOUT_REL_RRDoorMotorCmd_sig
            OUT_VeOUT_REL_FLDoorMotorPWM_pct_VeOUT_REL_FLDoorMotorPWM_pct: accessed-variable=VeOUT_REL_FLDoorMotorPWM_pct.VeOUT_REL_FLDoorMotorPWM_pct
            OUT_VeOUT_REL_FRDoorMotorPWM_pct_VeOUT_REL_FRDoorMotorPWM_pct: accessed-variable=VeOUT_REL_FRDoorMotorPWM_pct.VeOUT_REL_FRDoorMotorPWM_pct
            OUT_VeOUT_REL_RLDoorMotorPWM_pct_VeOUT_REL_RLDoorMotorPWM_pct: accessed-variable=VeOUT_REL_RLDoorMotorPWM_pct.VeOUT_REL_RLDoorMotorPWM_pct
            OUT_VeOUT_REL_RRDoorMotorPWM_pct_VeOUT_REL_RRDoorMotorPWM_pct: accessed-variable=VeOUT_REL_RRDoorMotorPWM_pct.VeOUT_REL_RRDoorMotorPWM_pct
package /Interfaces
  116 x sender receiver interface:
    VeOUT_PDU_BcmPowerStatusFeedback_sig
      data VeOUT_PDU_BcmPowerStatusFeedback_sig: category=VALUE, sw-calibration-access=READ-ONLY, type=UInt8
    VeINP_CAN_CdcDrvrDoorLockSet_sig
      data VeINP_CAN_CdcDrvrDoorLockSet_sig: category=VALUE, sw-calibration-access=READ-ONLY, type=UInt8
    VeINP_EPRM_BdcDrvrDoorLockSetSts_sig
      data VeINP_EPRM_BdcDrvrDoorLockSetSts_sig: category=VALUE, sw-calibration-access=READ-ONLY, type=UInt8
    VeOUT_DLK_BdcDrvrDoorLockSts_sig
      data VeOUT_DLK_BdcDrvrDoorLockSts_sig: category=VALUE, sw-calibration-access=READ-ONLY, type=UInt8
    VeOUT_SP_EspVehSpd_kmh
      data VeOUT_SP_EspVehSpd_kmh: category=VALUE, sw-calibration-access=READ-ONLY, type=UInt8
    VbINP_CAN_EspVehSpdVld_flg
      data VbINP_CAN_EspVehSpdVld_flg: category=BOOLEAN, sw-calibration-access=READ-ONLY, type=Boolean
    VeINP_CAN_VcuGearPosn_sig
      data VeINP_CAN_VcuGearPosn_sig: category=VALUE, sw-calibration-access=READ-ONLY, type=UInt8
    VbINP_HWA_FLDoorButton_flg
      data VbINP_HWA_FLDoorButton_flg: category=BOOLEAN, sw-calibration-access=READ-ONLY, type=Boolean
    VbINP_HWA_FRDoorButton_flg
      data VbINP_HWA_FRDoorButton_flg: category=BOOLEAN, sw-calibration-access=READ-ONLY, type=Boolean
    VbINP_HWA_RLDoorButton_flg
      data VbINP_HWA_RLDoorButton_flg: category=BOOLEAN, sw-calibration-access=READ-ONLY, type=Boolean
    VbINP_HWA_RRDoorButton_flg
      data VbINP_HWA_RRDoorButton_flg: category=BOOLEAN, sw-calibration-access=READ-ONLY, type=Boolean
    VmOUT_DLK_LockSrc_enum
      data VmOUT_DLK_LockSrc_enum: category=VALUE, sw-calibration-access=READ-ONLY, type=UInt8
    VbINP_HWA_LRChildLckSt_flg
      data VbINP_HWA_LRChildLckSt_flg: category=BOOLEAN, sw-calibration-access=READ-ONLY, type=Boolean
    VbINP_HWA_RRChildLckSt_flg
      data VbINP_HWA_RRChildLckSt_flg: category=BOOLEAN, sw-calibration-access=READ-ONLY, type=Boolean
    VbOUT_DLK_Unlock_flg
      data VbOUT_DLK_Unlock_flg: category=BOOLEAN, sw-calibration-access=READ-ONLY, type=Boolean
    VbINP_HWA_FLDoorOutButton_flg
      data VbINP_HWA_FLDoorOutButton_flg: category=BOOLEAN, sw-calibration-access=READ-ONLY, type=Boolean
    VbINP_HWA_FRDoorOutButton_flg
      data VbINP_HWA_FRDoorOutButton_flg: category=BOOLEAN, sw-calibration-access=READ-ONLY, type=Boolean
    VbINP_HWA_RLDoorOutButton_flg
      data VbINP_HWA_RLDoorOutButton_flg: category=BOOLEAN, sw-calibration-access=READ-ONLY, type=Boolean
    VbINP_HWA_RRDoorOutButton_flg
      data VbINP_HWA_RRDoorOutButton_flg: category=BOOLEAN, sw-calibration-access=READ-ONLY, type=Boolean
    VbINP_HWA_FLDoorHandleSW_flg
      data VbINP_HWA_FLDoorHandleSW_flg: category=BOOLEAN, sw-calibration-access=READ-ONLY, type=Boolean
    VbINP_HWA_FRDoorHandleSW_flg
      data VbINP_HWA_FRDoorHandleSW_flg: category=BOOLEAN, sw-calibration-access=READ-ONLY, type=Boolean
    VbINP_HWA_RLDoorHandleSW_flg
      data VbINP_HWA_RLDoorHandleSW_flg: category=BOOLEAN, sw-calibration-access=READ-ONLY, type=Boolean
    VbINP_HWA_RRDoorHandleSW_flg
      data VbINP_HWA_RRDoorHandleSW_flg: category=BOOLEAN, sw-calibration-access=READ-ONLY, type=Boolean
    VeINP_BLE_BDCBleKeyDoorCtrRequest_sig
      data VeINP_BLE_BDCBleKeyDoorCtrRequest_sig: category=VALUE, sw-calibration-access=READ-ONLY, type=UInt8
    VbINP_CAN_CdcAllDoorOpenButtonSts_flg
      data VbINP_CAN_CdcAllDoorOpenButtonSts_flg: category=BOOLEAN, sw-calibration-access=READ-ONLY, type=Boolean
    VeOUT_DLK_BCMPassengerDoorLockStatus_sig
      data VeOUT_DLK_BCMPassengerDoorLockStatus_sig: category=VALUE, sw-calibration-access=READ-ONLY, type=UInt8
    VbINP_CAN_CdcDrvrDoorButtonSts_flg
      data VbINP_CAN_CdcDrvrDoorButtonSts_flg: category=BOOLEAN, sw-calibration-access=READ-ONLY, type=Boolean
    VbINP_CAN_CdcPassDoorButtonSts_flg
      data VbINP_CAN_CdcPassDoorButtonSts_flg: category=BOOLEAN, sw-calibration-access=READ-ONLY, type=Boolean
    VbINP_CAN_CdcLeReDoorButtonSts_flg
      data VbINP_CAN_CdcLeReDoorButtonSts_flg: category=BOOLEAN, sw-calibration-access=READ-ONLY, type=Boolean
    VbINP_CAN_CdcRiReDoorButtonSts_flg
      data VbINP_CAN_CdcRiReDoorButtonSts_flg: category=BOOLEAN, sw-calibration-access=READ-ONLY, type=Boolean
    VbINP_CFG_ElectricalDoorCfg_flg
      data VbINP_CFG_ElectricalDoorCfg_flg: category=BOOLEAN, sw-calibration-access=READ-ONLY, type=Boolean
    VbINP_HWA_FLDoorAjar_flg
      data VbINP_HWA_FLDoorAjar_flg: category=BOOLEAN, sw-calibration-access=READ-ONLY, type=Boolean
    VbINP_HWA_FRDoorAjar_flg
      data VbINP_HWA_FRDoorAjar_flg: category=BOOLEAN, sw-calibration-access=READ-ONLY, type=Boolean
    VbINP_HWA_RLDoorAjar_flg
      data VbINP_HWA_RLDoorAjar_flg: category=BOOLEAN, sw-calibration-access=READ-ONLY, type=Boolean
    VbINP_HWA_RRDoorAjar_flg
      data VbINP_HWA_RRDoorAjar_flg: category=BOOLEAN, sw-calibration-access=READ-ONLY, type=Boolean
    VbINP_CAN_FLDCUCinchHomeSwitch_flg
      data VbINP_CAN_FLDCUCinchHomeSwitch_flg: category=BOOLEAN, sw-calibration-access=READ-ONLY, type=Boolean
    VbINP_CAN_FRDCUCinchHomeSwitch_flg
      data VbINP_CAN_FRDCUCinchHomeSwitch_flg: category=BOOLEAN, sw-calibration-access=READ-ONLY, type=Boolean
    VbINP_CAN_RLDCUCinchHomeSwitch_flg
      data VbINP_CAN_RLDCUCinchHomeSwitch_flg: category=BOOLEAN, sw-calibration-access=READ-ONLY, type=Boolean
    VbINP_CAN_RRDCUCinchHomeSwitch_flg
      data VbINP_CAN_RRDCUCinchHomeSwitch_flg: category=BOOLEAN, sw-calibration-access=READ-ONLY, type=Boolean
    VbINP_HWA_FLCinchHomeSW_flg
      data VbINP_HWA_FLCinchHomeSW_flg: category=BOOLEAN, sw-calibration-access=READ-ONLY, type=Boolean
    VbINP_HWA_FRCinchHomeSW_flg
      data VbINP_HWA_FRCinchHomeSW_flg: category=BOOLEAN, sw-calibration-access=READ-ONLY, type=Boolean
    VbINP_HWA_RLCinchHomeSW_flg
      data VbINP_HWA_RLCinchHomeSW_flg: category=BOOLEAN, sw-calibration-access=READ-ONLY, type=Boolean
    VbINP_HWA_RRCinchHomeSW_flg
      data VbINP_HWA_RRCinchHomeSW_flg: category=BOOLEAN, sw-calibration-access=READ-ONLY, type=Boolean
    VeOUT_DHM_BDCDrvrDoorHndSts_sig
      data VeOUT_DHM_BDCDrvrDoorHndSts_sig: category=VALUE, sw-calibration-access=READ-ONLY, type=UInt8
    VeOUT_DHM_BDCPassDoorHndSts_sig
      data VeOUT_DHM_BDCPassDoorHndSts_sig: category=VALUE, sw-calibration-access=READ-ONLY, type=UInt8
    VeOUT_DHM_BDCLeReDoorHndSts_sig
      data VeOUT_DHM_BDCLeReDoorHndSts_sig: category=VALUE, sw-calibration-access=READ-ONLY, type=UInt8
    VeOUT_DHM_BDCRiReDoorHndSts_sig
      data VeOUT_DHM_BDCRiReDoorHndSts_sig: category=VALUE, sw-calibration-access=READ-ONLY, type=UInt8
    VbOUT_SP_CrashOutpSts_flg
      data VbOUT_SP_CrashOutpSts_flg: category=BOOLEAN, sw-calibration-access=READ-ONLY, type=Boolean
    VbOUT_DLK_BdcDrvrDoorLockOpenReq_flg
      data VbOUT_DLK_BdcDrvrDoorLockOpenReq_flg: category=BOOLEAN, sw-calibration-access=READ-ONLY, type=Boolean
    VbOUT_DHM_BdcDrivDoorHandButtonSts_flg
      data VbOUT_DHM_BdcDrivDoorHandButtonSts_flg: category=BOOLEAN, sw-calibration-access=READ-ONLY, type=Boolean
    VbOUT_DHM_BdcPassDoorHandButtonSts_flg
      data VbOUT_DHM_BdcPassDoorHandButtonSts_flg: category=BOOLEAN, sw-calibration-access=READ-ONLY, type=Boolean
    VeINP_BLE_BleKey1Posn_sig
      data VeINP_BLE_BleKey1Posn_sig: category=VALUE, sw-calibration-access=READ-ONLY, type=UInt8
    VeINP_BLE_BleKey2Posn_sig
      data VeINP_BLE_BleKey2Posn_sig: category=VALUE, sw-calibration-access=READ-ONLY, type=UInt8
    VeINP_BLE_BleKey3Posn_sig
      data VeINP_BLE_BleKey3Posn_sig: category=VALUE, sw-calibration-access=READ-ONLY, type=UInt8
    VuINP_CFG_TiLongPressHndlBtn_sig
      data VuINP_CFG_TiLongPressHndlBtn_sig: category=VALUE, sw-calibration-access=READ-ONLY, type=UInt16
    VuINP_CFG_OutsideDoorOpenDelay_sig
      data VuINP_CFG_OutsideDoorOpenDelay_sig: category=VALUE, sw-calibration-access=READ-ONLY, type=UInt16
    VuINP_CFG_InsideDoorOpenDelay_sig
      data VuINP_CFG_InsideDoorOpenDelay_sig: category=VALUE, sw-calibration-access=READ-ONLY, type=UInt16
    VuINP_CFG_Ti2xPressDoorSw_sig
      data VuINP_CFG_Ti2xPressDoorSw_sig: category=VALUE, sw-calibration-access=READ-ONLY, type=UInt16
    VuINP_CFG_TiRelsActv_sig
      data VuINP_CFG_TiRelsActv_sig: category=VALUE, sw-calibration-access=READ-ONLY, type=UInt16
    VeINP_CFG_TiRelsBrakeActv_sig
      data VeINP_CFG_TiRelsBrakeActv_sig: category=VALUE, sw-calibration-access=READ-ONLY, type=UInt8
    VuINP_CFG_TiRelsResetActv_sig
      data VuINP_CFG_TiRelsResetActv_sig: category=VALUE, sw-calibration-access=READ-ONLY, type=UInt16
    VuINP_CFG_TiRelsBrakehold_sig
      data VuINP_CFG_TiRelsBrakehold_sig: category=VALUE, sw-calibration-access=READ-ONLY, type=UInt16
    VuINP_CFG_TiRelsBrakeholdDelay_sig
      data VuINP_CFG_TiRelsBrakeholdDelay_sig: category=VALUE, sw-calibration-access=READ-ONLY, type=UInt16
    VuINP_CFG_TiIceBrakeActv_sig
      data VuINP_CFG_TiIceBrakeActv_sig: category=VALUE, sw-calibration-access=READ-ONLY, type=UInt16
    VeINP_CFG_VoltRelsActv_sig
      data VeINP_CFG_VoltRelsActv_sig: category=VALUE, sw-calibration-access=READ-ONLY, type=UInt8
    VeINP_CFG_VoltRelsBrakeActv_sig
      data VeINP_CFG_VoltRelsBrakeActv_sig: category=VALUE, sw-calibration-access=READ-ONLY, type=UInt8
    VeINP_CFG_TiCrashRelsDiable_sig
      data VeINP_CFG_TiCrashRelsDiable_sig: category=VALUE, sw-calibration-access=READ-ONLY, type=UInt8
    VeINP_CFG_TiBleOpenDoorFb_sig
      data VeINP_CFG_TiBleOpenDoorFb_sig: category=VALUE, sw-calibration-access=READ-ONLY, type=UInt8
    VeINP_CFG_TiBleClsDoorFb_sig
      data VeINP_CFG_TiBleClsDoorFb_sig: category=VALUE, sw-calibration-access=READ-ONLY, type=UInt8
    VeINP_HWA_Voltage_100mV
      data VeINP_HWA_Voltage_100mV: category=VALUE, sw-calibration-access=READ-ONLY, type=UInt8
    VbINP_HWA_FLDoorOpenSW_flg
      data VbINP_HWA_FLDoorOpenSW_flg: category=BOOLEAN, sw-calibration-access=READ-ONLY, type=Boolean
    VbINP_HWA_FRDoorOpenSW_flg
      data VbINP_HWA_FRDoorOpenSW_flg: category=BOOLEAN, sw-calibration-access=READ-ONLY, type=Boolean
    VbINP_HWA_RLDoorOpenSW_flg
      data VbINP_HWA_RLDoorOpenSW_flg: category=BOOLEAN, sw-calibration-access=READ-ONLY, type=Boolean
    VbINP_HWA_RRDoorOpenSW_flg
      data VbINP_HWA_RRDoorOpenSW_flg: category=BOOLEAN, sw-calibration-access=READ-ONLY, type=Boolean
    VbOUT_REL_BdcDrvrDoorLockSetSts_flg
      data VbOUT_REL_BdcDrvrDoorLockSetSts_flg: category=BOOLEAN, sw-calibration-access=READ-ONLY, type=Boolean
    VbOUT_REL_BdcDrvrDoorLockSetStsToEE_flg
      data VbOUT_REL_BdcDrvrDoorLockSetStsToEE_flg: category=BOOLEAN, sw-calibration-access=READ-ONLY, type=Boolean
    VeOUT_REL_BcmDrvrDoorSwtSts_sig
      data VeOUT_REL_BcmDrvrDoorSwtSts_sig: category=VALUE, sw-calibration-access=READ-ONLY, type=UInt8
    VeOUT_REL_BcmPassDoorSwtSts_sig
      data VeOUT_REL_BcmPassDoorSwtSts_sig: category=VALUE, sw-calibration-access=READ-ONLY, type=UInt8
    VeOUT_REL_BcmLeReDoorSwtSts_sig
      data VeOUT_REL_BcmLeReDoorSwtSts_sig: category=VALUE, sw-calibration-access=READ-ONLY, type=UInt8
    VeOUT_REL_BcmRiReDoorSwtSts_sig
      data VeOUT_REL_BcmRiReDoorSwtSts_sig: category=VALUE, sw-calibration-access=READ-ONLY, type=UInt8
    VeOUT_REL_BdcLFDoorRatSts_sig
      data VeOUT_REL_BdcLFDoorRatSts_sig: category=VALUE, sw-calibration-access=READ-ONLY, type=UInt8
    VeOUT_REL_BdcRFDoorRatSts_sig
      data VeOUT_REL_BdcRFDoorRatSts_sig: category=VALUE, sw-calibration-access=READ-ONLY, type=UInt8
    VeOUT_REL_BdcLRDoorRatSts_sig
      data VeOUT_REL_BdcLRDoorRatSts_sig: category=VALUE, sw-calibration-access=READ-ONLY, type=UInt8
    VeOUT_REL_BdcRRDoorRatSts_sig
      data VeOUT_REL_BdcRRDoorRatSts_sig: category=VALUE, sw-calibration-access=READ-ONLY, type=UInt8
    VbOUT_REL_BcmDrvrDoorHandleReq_flg
      data VbOUT_REL_BcmDrvrDoorHandleReq_flg: category=BOOLEAN, sw-calibration-access=READ-ONLY, type=Boolean
    VbOUT_REL_BcmPassDoorHandleReq_flg
      data VbOUT_REL_BcmPassDoorHandleReq_flg: category=BOOLEAN, sw-calibration-access=READ-ONLY, type=Boolean
    VbOUT_REL_BcmLeReDoorHandleReq_flg
      data VbOUT_REL_BcmLeReDoorHandleReq_flg: category=BOOLEAN, sw-calibration-access=READ-ONLY, type=Boolean
    VbOUT_REL_BcmBcmRiReDoorHandleReq_flg
      data VbOUT_REL_BcmBcmRiReDoorHandleReq_flg: category=BOOLEAN, sw-calibration-access=READ-ONLY, type=Boolean
    VbOUT_REL_FLDoorHndlBtnSig_flg
      data VbOUT_REL_FLDoorHndlBtnSig_flg: category=BOOLEAN, sw-calibration-access=READ-ONLY, type=Boolean
    VbOUT_REL_FRDoorHndlBtnSig_flg
      data VbOUT_REL_FRDoorHndlBtnSig_flg: category=BOOLEAN, sw-calibration-access=READ-ONLY, type=Boolean
    VbOUT_REL_RLDoorHndlBtnSig_flg
      data VbOUT_REL_RLDoorHndlBtnSig_flg: category=BOOLEAN, sw-calibration-access=READ-ONLY, type=Boolean
    VbOUT_REL_RRDoorHndlBtnSig_flg
      data VbOUT_REL_RRDoorHndlBtnSig_flg: category=BOOLEAN, sw-calibration-access=READ-ONLY, type=Boolean
    VeOUT_REL_DLKReqUnlock_sig
      data VeOUT_REL_DLKReqUnlock_sig: category=VALUE, sw-calibration-access=READ-ONLY, type=UInt8
    VbOUT_REL_FLDoorRlsReq_flg
      data VbOUT_REL_FLDoorRlsReq_flg: category=BOOLEAN, sw-calibration-access=READ-ONLY, type=Boolean
    VbOUT_REL_FRDoorRlsReq_flg
      data VbOUT_REL_FRDoorRlsReq_flg: category=BOOLEAN, sw-calibration-access=READ-ONLY, type=Boolean
    VbOUT_REL_RLDoorRlsReq_flg
      data VbOUT_REL_RLDoorRlsReq_flg: category=BOOLEAN, sw-calibration-access=READ-ONLY, type=Boolean
    VbOUT_REL_RRDoorRlsReq_flg
      data VbOUT_REL_RRDoorRlsReq_flg: category=BOOLEAN, sw-calibration-access=READ-ONLY, type=Boolean
    VeOUT_REL_FLDoorMotorSts_sig
      data VeOUT_REL_FLDoorMotorSts_sig: category=VALUE, sw-calibration-access=READ-ONLY, type=UInt8
    VeOUT_REL_FRDoorMotorSts_sig
      data VeOUT_REL_FRDoorMotorSts_sig: category=VALUE, sw-calibration-access=READ-ONLY, type=UInt8
    VeOUT_REL_RLDoorMotorSts_sig
      data VeOUT_REL_RLDoorMotorSts_sig: category=VALUE, sw-calibration-access=READ-ONLY, type=UInt8
    VeOUT_REL_RRDoorMotorSts_sig
      data VeOUT_REL_RRDoorMotorSts_sig: category=VALUE, sw-calibration-access=READ-ONLY, type=UInt8
    VbOUT_REL_FLDoorMotorErrSts_flg
      data VbOUT_REL_FLDoorMotorErrSts_flg: category=BOOLEAN, sw-calibration-access=READ-ONLY, type=Boolean
    VbOUT_REL_FRDoorMotorErrSts_flg
      data VbOUT_REL_FRDoorMotorErrSts_flg: category=BOOLEAN, sw-calibration-access=READ-ONLY, type=Boolean
    VbOUT_REL_RLDoorMotorErrSts_flg
      data VbOUT_REL_RLDoorMotorErrSts_flg: category=BOOLEAN, sw-calibration-access=READ-ONLY, type=Boolean
    VbOUT_REL_RRDoorMotorErrSts_flg
      data VbOUT_REL_RRDoorMotorErrSts_flg: category=BOOLEAN, sw-calibration-access=READ-ONLY, type=Boolean
    VeOUT_REL_BDCBleKeyClsDoorRsp_sig
      data VeOUT_REL_BDCBleKeyClsDoorRsp_sig: category=VALUE, sw-calibration-access=READ-ONLY, type=UInt8
    VeOUT_REL_BDCBleKeyOpenDoorRsp_sig
      data VeOUT_REL_BDCBleKeyOpenDoorRsp_sig: category=VALUE, sw-calibration-access=READ-ONLY, type=UInt8
    VeOUT_REL_BDCBleKeyDoorCtrRequest_sig
      data VeOUT_REL_BDCBleKeyDoorCtrRequest_sig: category=VALUE, sw-calibration-access=READ-ONLY, type=UInt8
    VeOUT_REL_FLDoorMotorCmd_sig
      data VeOUT_REL_FLDoorMotorCmd_sig: category=VALUE, sw-calibration-access=READ-ONLY, type=UInt8
    VeOUT_REL_FRDoorMotorCmd_sig
      data VeOUT_REL_FRDoorMotorCmd_sig: category=VALUE, sw-calibration-access=READ-ONLY, type=UInt8
    VeOUT_REL_RLDoorMotorCmd_sig
      data VeOUT_REL_RLDoorMotorCmd_sig: category=VALUE, sw-calibration-access=READ-ONLY, type=UInt8
    VeOUT_REL_RRDoorMotorCmd_sig
      data VeOUT_REL_RRDoorMotorCmd_sig: category=VALUE, sw-calibration-access=READ-ONLY, type=UInt8
    VeOUT_REL_FLDoorMotorPWM_pct
      data VeOUT_REL_FLDoorMotorPWM_pct: category=VALUE, sw-calibration-access=READ-ONLY, type=UInt8
    VeOUT_REL_FRDoorMotorPWM_pct
      data VeOUT_REL_FRDoorMotorPWM_pct: category=VALUE, sw-calibration-access=READ-ONLY, type=UInt8
    VeOUT_REL_RLDoorMotorPWM_pct
      data VeOUT_REL_RLDoorMotorPWM_pct: category=VALUE, sw-calibration-access=READ-ONLY, type=UInt8
    VeOUT_REL_RRDoorMotorPWM_pct
      data VeOUT_REL_RRDoorMotorPWM_pct: category=VALUE, sw-calibration-access=READ-ONLY, type=UInt8
package /REL_imp
  swc implementation REL: behavior=REL
    code-descriptors:
      code Default: artifact-descriptors=autosar-engineering-object={short-label=Default, category=SWSRC}
package /DataTypes/SwAddrMethods
  sw addr method CODE: section-type=CODE
  sw addr method CONST: section-type=CONST
  sw addr method VAR: section-type=VAR
package /DataTypes/ApplicationDataTypes
  7 x app type, all with sw-calibration-access=READ-WRITE:
    Boolean: category=BOOLEAN, compu {0=FALSE, 1=TRUE}
    UInt8: category=VALUE, compu {identical}, range phys 0..255
    SInt8: category=VALUE, compu {identical}, range phys -128..127
    UInt16: category=VALUE, compu {identical}, range phys 0..65535
    SInt16: category=VALUE, compu {identical}, range phys -32768..32767
    UInt32: category=VALUE, compu {identical}, range phys 0..4294967295
    SInt32: category=VALUE, compu {identical}, range phys -2147483648..2147483647
  4 x application record data type, all with category=STRUCTURE, sw-calibration-access=READ-WRITE:
    MIR_EPRMSts_STRUCT
      8 x application record element, all with category=VALUE, type=UInt8:
        L_DrvMode_VtcPos
        L_DrvMode_HrzPos
        R_DrvMode_VtcPos
        R_DrvMode_HrzPos
        R_TiltMode_VtcPos
        R_TiltMode_HrzPos
        L_TiltMode_VtcPos
        L_TiltMode_HrzPos
    MIR_DEBUG_STRUCT
      8 x application record element, all with category=VALUE, type=UInt8:
        ManulaAdjDebug
        MemoryDebug
        ManulaAdjBeforeDebug
        ManulatrjDebug
        MirFlipStepDebug
        SaveDebug_Mode
        LDebug_AutoStep
        RDebug_AutoStep
    MIR_ADJ_STRUCT
      4 x application record element, all with category=VALUE, type=UInt8:
        R_Mir_Current_HrzPos
        R_Mir_Current_VtcPos
        L_Mir_Current_VtcPos
        L_Mir_Current_HrzPos
    TURN_DIAG_STRUCT
      5 x application record element:
        OpenLoad: category=BOOLEAN, type=Boolean
        Overload: category=BOOLEAN, type=Boolean
        NormA2D: category=VALUE, type=UInt8
        Turn_LTH: category=VALUE, type=UInt8
        TurnCalib_th: category=VALUE, type=UInt8
  application array data type rt_Array_UInt8_8: category=ARRAY, sw-calibration-access=READ-WRITE
    element rt_Array_UInt8_8: category=VALUE, type=UInt8, array-size-semantics=FIXED-SIZE, max-number-of-elements=8
  application array data type rt_Array_UInt8_20: category=ARRAY, sw-calibration-access=READ-WRITE
    element rt_Array_UInt8_20: category=VALUE, type=UInt8, array-size-semantics=FIXED-SIZE, max-number-of-elements=20
package /DataTypes/ApplicationDataTypes/DataConstrs
  range DC_MIR_EPRMSts_STRUCT: phys 0
  range DC_MIR_DEBUG_STRUCT: phys 0
  range DC_MIR_ADJ_STRUCT: phys 0
  range DC_TURN_DIAG_STRUCT: phys 0
package /DataTypes/ImplementationDataTypes
  6 x impl type:
    MIR_EPRMSts_STRUCT: category=STRUCTURE
      8 x element, all with category=TYPE_REFERENCE, implementation-data-type=UInt8:
        L_DrvMode_VtcPos
        L_DrvMode_HrzPos
        R_DrvMode_VtcPos
        R_DrvMode_HrzPos
        R_TiltMode_VtcPos
        R_TiltMode_HrzPos
        L_TiltMode_VtcPos
        L_TiltMode_HrzPos
    MIR_DEBUG_STRUCT: category=STRUCTURE
      8 x element, all with category=TYPE_REFERENCE, implementation-data-type=UInt8:
        ManulaAdjDebug
        MemoryDebug
        ManulaAdjBeforeDebug
        ManulatrjDebug
        MirFlipStepDebug
        SaveDebug_Mode
        LDebug_AutoStep
        RDebug_AutoStep
    MIR_ADJ_STRUCT: category=STRUCTURE
      4 x element, all with category=TYPE_REFERENCE, implementation-data-type=UInt8:
        R_Mir_Current_HrzPos
        R_Mir_Current_VtcPos
        L_Mir_Current_VtcPos
        L_Mir_Current_HrzPos
    TURN_DIAG_STRUCT: category=STRUCTURE
      5 x element, all with category=TYPE_REFERENCE:
        OpenLoad: implementation-data-type=Boolean
        Overload: implementation-data-type=Boolean
        NormA2D: implementation-data-type=UInt8
        Turn_LTH: implementation-data-type=UInt8
        TurnCalib_th: implementation-data-type=UInt8
    rt_Array_UInt8_8: category=ARRAY
      element rt_Array_UInt8_8: array-size=8, array-size-semantics=FIXED-SIZE, implementation-data-type=UInt8
    rt_Array_UInt8_20: category=ARRAY
      element rt_Array_UInt8_20: array-size=20, array-size-semantics=FIXED-SIZE, implementation-data-type=UInt8
package /DataTypes/Units
  unit NoUnit: factor-si-to-unit=1, offset-si-to-unit=0
package /DataTypes/DataTypeMappings
  data type mapping set DataTypeMappingsSet
    data-type-maps:
      application-data-type=Boolean, implementation-data-type=Boolean
      application-data-type=UInt8, implementation-data-type=UInt8
      application-data-type=SInt8, implementation-data-type=SInt8
      application-data-type=UInt16, implementation-data-type=UInt16
      application-data-type=SInt16, implementation-data-type=SInt16
      application-data-type=UInt32, implementation-data-type=UInt32
      application-data-type=SInt32, implementation-data-type=SInt32
      application-data-type=MIR_EPRMSts_STRUCT, implementation-data-type=MIR_EPRMSts_STRUCT
      application-data-type=MIR_DEBUG_STRUCT, implementation-data-type=MIR_DEBUG_STRUCT
      application-data-type=MIR_ADJ_STRUCT, implementation-data-type=MIR_ADJ_STRUCT
      application-data-type=TURN_DIAG_STRUCT, implementation-data-type=TURN_DIAG_STRUCT
      application-data-type=rt_Array_UInt8_8, implementation-data-type=rt_Array_UInt8_8
      application-data-type=rt_Array_UInt8_20, implementation-data-type=rt_Array_UInt8_20
